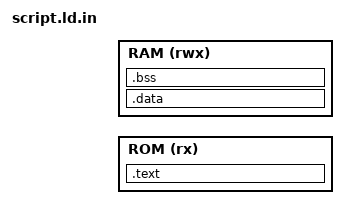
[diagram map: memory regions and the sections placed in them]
/* This file is automatically generated */
OUTPUT_FORMAT("elf32-littlearm", "elf32-littlearm", "elf32-littlearm")
OUTPUT_ARCH(arm)
MEMORY
{
ROM (rx) : ORIGIN = @ROMSTART@, LENGTH = @ROMLEN@
RAM (rwx) : ORIGIN = @RAMSTART@, LENGTH = @RAMLEN@
}
SECTIONS
{
.text :
{
KEEP(*(.isr_vector))
*(.rodata.usbd_devfs)
*(.rodata.usbd_devfs_asm)
*(.rodata.usbd_otgfs)
*(.rodata_usbd_otghs)
*(.text.usbd_poll)
*(.text*)
*(.rodata*)
} > ROM
. = ALIGN(4);
__etext = .;
. = . + SIZEOF(.data);
__app_start = ALIGN(@APPALIGN@);
.data : AT (__etext)
{
. = ALIGN(4);
__data_start__ = .;
*(.data*)
. = ALIGN(4);
__data_end__ = .;
} > RAM
.bss (NOLOAD):
{
. = ALIGN(4);
__bss_start__ = .;
*(.bss*)
*(COMMON)
. = ALIGN(4);
__bss_end__ = .;
} > RAM
PROVIDE(__romend = ORIGIN(ROM) + LENGTH(ROM));
PROVIDE(__stack = ORIGIN(RAM) + LENGTH(RAM) - 4);
}
